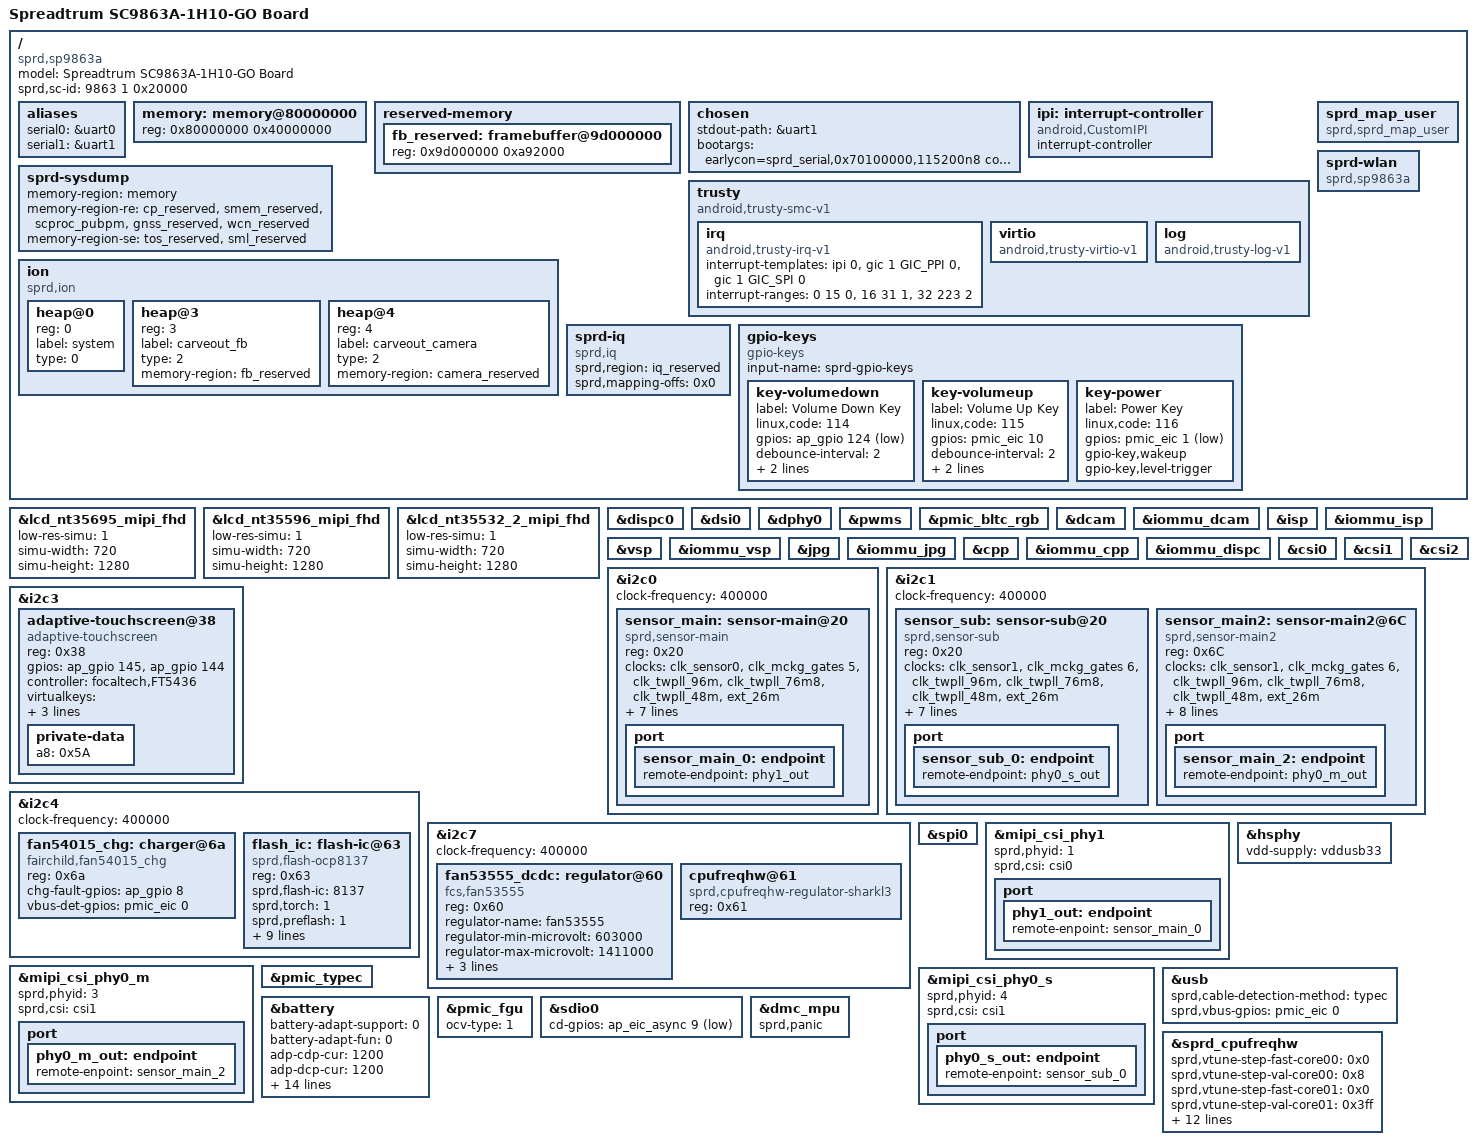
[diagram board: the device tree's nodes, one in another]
/*
 * Spreadtrum sharkl3 board DTS file
 *
 * Copyright (C) 2017, Spreadtrum Communications Inc.
 *
 * This file is licensed under a dual GPLv2 or X11 license.
 */
/dts-v1/;

#include "sc9863a.dtsi"
#include "sp9863a-go-common.dtsi"
#include "sc9863a-wcn.dtsi"

/ {
	model = "Spreadtrum SC9863A-1H10-GO Board";

	compatible = "sprd,sp9863a", "sprd,sc9863a";

	sprd,sc-id = <9863 1 0x20000>;

	aliases {
		serial0 = &uart0;
		serial1 = &uart1;
	};

	memory: memory@80000000 {
		device_type = "memory";
		reg = <0x80000000 0x40000000>;
	};

	reserved-memory {
		/* fb_size(HD): 3 * (head + payload) = 0xa91580, 4k align: 0xa92000 */
		fb_reserved: framebuffer@9d000000{
			reg = <0x9d000000 0xa92000>;
		};
	};

	chosen {
		stdout-path = &uart1;
		bootargs = "earlycon=sprd_serial,0x70100000,115200n8 console=ttyS1,115200n8 loglevel=1 init=/init root=/dev/mmcblk0p30 rootfstype=ext4 ro rootwait androidboot.hardware=s9863a1h10_go_32b androidboot.dtbo_idx=0 swiotlb=1 vmalloc=300M";
	};

	ipi: interrupt-controller {
		compatible = "android,CustomIPI";
		#interrupt-cells = <1>;
		interrupt-controller;
	};

	trusty {
		compatible = "android,trusty-smc-v1";

		irq {
			compatible = "android,trusty-irq-v1";
			interrupt-templates = <&ipi 0>,
						<&gic 1 GIC_PPI 0>,
						<&gic 1 GIC_SPI 0>;
			interrupt-ranges = < 0  15 0>,
						<16  31 1>,
						<32 223 2>;
		};

		virtio {
			compatible = "android,trusty-virtio-v1";
		};

		log {
			compatible = "android,trusty-log-v1";
		};
	};

	sprd-sysdump {
		memory-region = <&memory>;
		memory-region-re = <&cp_reserved>, <&smem_reserved>,
				   <&scproc_pubpm>, <&gnss_reserved>,
				   <&wcn_reserved>;
		memory-region-se = <&tos_reserved>, <&sml_reserved>;
	};

	sprd_map_user {
		compatible = "sprd,sprd_map_user";
	};

	ion {
		compatible = "sprd,ion";
		#address-cells = <1>;
		#size-cells = <0>;

		heap@0 {
			reg = <0>;
			label = "system";
			type = <0>;
		};

		heap@3 {
			reg = <3>;
			label = "carveout_fb";
			type = <2>;
			memory-region = <&fb_reserved>;
		};

		heap@4 {
			reg = <4>;
			label = "carveout_camera";
			type = <2>;
			memory-region = <&camera_reserved>;
		};
	};

	sprd-iq {
		compatible = "sprd,iq";
		sprd,region = <&iq_reserved>;
		sprd,mapping-offs = <0x0>;
	};

	sprd-wlan {
		compatible = "sprd,sp9863a";
	};

	gpio-keys {
		compatible = "gpio-keys";
		input-name = "sprd-gpio-keys";
		status = "okay";

		key-volumedown {
			label = "Volume Down Key";
			linux,code = <114>;
			gpios = <&ap_gpio 124 1>;
			debounce-interval = <2>;
			gpio-key,wakeup;
			gpio-key,level-trigger;
		};

		key-volumeup {
			label = "Volume Up Key";
			linux,code = <115>;
			gpios = <&pmic_eic 10 0>;
			debounce-interval = <2>;
			gpio-key,wakeup;
			gpio-key,level-trigger;
		};

		key-power {
			label = "Power Key";
			linux,code = <116>;
			gpios = <&pmic_eic 1 1>;
			gpio-key,wakeup;
			gpio-key,level-trigger;
		};
	};

};

&lcd_nt35695_mipi_fhd{
	low-res-simu = <1>;
	simu-width = <720>;
	simu-height = <1280>;
};

&lcd_nt35596_mipi_fhd{
	low-res-simu = <1>;
	simu-width = <720>;
	simu-height = <1280>;
};

&lcd_nt35532_2_mipi_fhd{
	low-res-simu = <1>;
	simu-width = <720>;
	simu-height = <1280>;
};

&dispc0 {
	status = "okay";
};

&dsi0 {
	status = "okay";
};

&dphy0 {
	status = "okay";
};

&pwms {
	status = "okay";
};

&pmic_bltc_rgb {
	status = "okay";
};

&dcam {
	status = "okay";
};

&iommu_dcam {
	status = "okay";
};

&isp {
	status = "okay";
};

&iommu_isp {
	status = "okay";
};

&vsp {
	status = "okay";
};

&iommu_vsp {
	status = "okay";
};

&jpg {
	status = "okay";
};

&iommu_jpg {
	status = "okay";
};

&cpp {
	status = "okay";
};

&iommu_cpp {
	status = "okay";
};

&iommu_dispc {
	status = "okay";
};

&csi0 {
	status = "okay";
};

&csi1 {
	status = "okay";
};

&csi2 {
	status = "okay";
};

&i2c0 {
	status = "okay";
	clock-frequency = <400000>;

	sensor_main: sensor-main@20 {
		compatible = "sprd,sensor-main";
		reg = <0x20>;
		clock-names = "clk_src","sensor_eb",
			"clk_96m","clk_76m8",
			"clk_48m","clk_26m";
		clocks = <&clk_sensor0>, <&clk_mckg_gates 5>,
			<&clk_twpll_96m>,<&clk_twpll_76m8>,
			<&clk_twpll_48m>,<&ext_26m>;
		vddio-supply = <&vddcamio>;
		vddcama-supply = <&vddcama>;
		vddcamd-supply = <&vddcamd>;
		vddcammot-supply = <&vddcammot>;
		reset-gpios = <&ap_gpio 44 0>;
		power-down-gpios = <&ap_gpio 46 0>;
		host = "dcam0";
		port {
			sensor_main_0: endpoint {
				remote-endpoint = <&phy1_out>;
			};
		};
	};
};

&i2c1 {
	status = "okay";
	clock-frequency = <400000>;

	sensor_sub: sensor-sub@20 {
		compatible = "sprd,sensor-sub";
		reg = <0x20>;
		clock-names = "clk_src","sensor_eb",
			"clk_96m","clk_76m8",
			"clk_48m","clk_26m";
		clocks = <&clk_sensor1>, <&clk_mckg_gates 6>,
			<&clk_twpll_96m>,<&clk_twpll_76m8>,
			<&clk_twpll_48m>,<&ext_26m>;
		vddio-supply = <&vddcamio>;
		vddcama-supply = <&vddcama>;
		vddcamd-supply = <&vddcamd>;
		vddcammot-supply = <&vddcammot>;
		reset-gpios = <&ap_gpio 41 0>;
		power-down-gpios = <&ap_gpio 40 0>;
		host = "dcam1";
		port {
			sensor_sub_0: endpoint {
				remote-endpoint = <&phy0_s_out>;
			};
		};
	};

	sensor_main2: sensor-main2@6C {
		compatible = "sprd,sensor-main2";
		reg = <0x6C>;
		clock-names = "clk_src","sensor_eb",
			"clk_96m","clk_76m8",
			"clk_48m","clk_26m";
		clocks = <&clk_sensor1>, <&clk_mckg_gates 6>,
			<&clk_twpll_96m>,<&clk_twpll_76m8>,
			<&clk_twpll_48m>,<&ext_26m>;
		vddio-supply = <&vddcamio>;
		vddcama-supply = <&vddcama>;
		vddcamd-supply = <&vddcamd>;
		vddcammot-supply = <&vddcammot>;
		dvdd-gpios=<&ap_gpio 62 0>;
		reset-gpios = <&ap_gpio 45 0>;
		power-down-gpios = <&ap_gpio 47 0>;
		host = "dcam1";
		port {
			sensor_main_2: endpoint {
				remote-endpoint = <&phy0_m_out>;
			};
		};
	};
};

&i2c3 {
	status = "okay";

	adaptive-touchscreen@38 {
		compatible = "adaptive-touchscreen";
		reg = <0x38>;
		gpios = <&ap_gpio 145 0
			&ap_gpio 144 0>;
		controller = "focaltech,FT5436";
		virtualkeys = <580 60 1320 60 45
			172 360 1320 60 45
			158 600 1320 60 45>;
		surface-width = <720>;
		surface-height = <1280>;
		private-data {
			a8 = /bits/ 8 <0x5A>;
		};
	};
};

&i2c4 {
	status = "okay";
	clock-frequency = <400000>;

	fan54015_chg: charger@6a {
		compatible = "fairchild,fan54015_chg";
		reg = <0x6a>;
		chg-fault-gpios = <&ap_gpio 8 0>;
		vbus-det-gpios = <&pmic_eic 0 0>;
	};

	flash_ic: flash-ic@63 {
		compatible = "sprd,flash-ocp8137";
		reg = <0x63>;
		sprd,flash-ic = <8137>;
		sprd,torch = <1>;
		sprd,preflash = <1>;
		sprd,highlight = <1>;
		sprd,torch-level = <128>;
		sprd,preflash-level = <128>;
		sprd,highlight-level = <128>;
		sprd,lvfm-enable = <1>;
		flash-torch-en-gpios = <&ap_gpio 88 0>;
		flash-chip-en-gpios = <&ap_gpio 89 0>;
		flash-en-gpios = <&ap_gpio 76 0>;
		flash-sync-gpios = <&ap_gpio 141 0>;
	};
};

&i2c7 {
	status = "okay";
	clock-frequency = <400000>;

	fan53555_dcdc: regulator@60 {
		compatible = "fcs,fan53555";
		reg = <0x60>;
		regulator-name = "fan53555";
		regulator-min-microvolt = <603000>;
		regulator-max-microvolt = <1411000>;
		regulator-ramp-delay = <64000>;
		regulator-always-on;
		fcs,suspend-voltage-selector = <1>;
	};

	/*virtual i2c device for cpu hw dvfs*/
	cpufreqhw@61 {
		compatible = "sprd,cpufreqhw-regulator-sharkl3";
		reg = <0x61>;
	};
};

&spi0 {
	/*used for fingerprint sensor*/
	status = "okay";
};

&mipi_csi_phy1 {
	status = "okay";
	sprd,phyid = <1>;
	sprd,csi = <&csi0>;
	status = "okay";
	port {
		phy1_out: endpoint {
			remote-enpoint = <&sensor_main_0>;
		};
	};
};

&mipi_csi_phy0_m {
	status = "okay";
	sprd,phyid = <3>;
	sprd,csi = <&csi1>;
	status = "okay";
	port {
		phy0_m_out: endpoint {
			remote-enpoint = <&sensor_main_2>;
		};
	};
};

&mipi_csi_phy0_s {
	status = "okay";
	sprd,phyid = <4>;
	sprd,csi = <&csi1>;
	status = "okay";
	port {
		phy0_s_out: endpoint {
			remote-enpoint = <&sensor_sub_0>;
		};
	};
};

&hsphy {
	vdd-supply = <&vddusb33>;
};

&usb {
	sprd,cable-detection-method = "typec";
	sprd,vbus-gpios = <&pmic_eic 0 0>;
};

&pmic_typec {
	status = "okay";
};

&battery {
	battery-adapt-support = <0>;
	battery-adapt-fun = <0>;
	adp-cdp-cur = <1200>;
	adp-dcp-cur = <1200>;
	adp-sdp-cur = <550>;
	adp-unknown-cur = <550>;
	chg-end-vol = <4350>;
	chg-end-vol-check = <4330>;
	chg-bat-safety-vol = <4430>;
	rechg-vol = <4270>;
	rsense-real = <200>;
	rint = <320>;
	cnom = <2780>;
	chg-polling-time = <10>;
	ocv-tab-vol = <4360 4249 4189 4133 4081 4034 3991
			3953 3910 3866 3836 3813 3795 3782
			3774 3765 3750 3726 3687 3658 3400>;
	ocv-tab-cap = <100  95   90   85   80   75   70
			65   60   55   50   45   40   35
			30   25   20   15   10   5    0>;
};

&pmic_fgu {
	ocv-type = <1>;
};

&sdio0 {
	 cd-gpios = <&ap_eic_async 9 1>;
};

&dmc_mpu {
	status = "okay";
	sprd,panic;
};

&sprd_cpufreqhw {
	sprd,vtune-step-fast-core00 = <0x0>;
	sprd,vtune-step-val-core00 = <0x8>;
	sprd,vtune-step-fast-core01 = <0x0>;
	sprd,vtune-step-val-core01 = <0x3ff>;
	sprd,vtune-vld-bit-core01 = <0x3f>;
	sprd,vtune-vld-bit-core00 = <0x3ff>;
	/*chnl0-[3:0],chnl0-[7:4],chnl2-[11:8]*/
	sprd,chnl-in-i2c = <0x000>;
	/*chnl_0-core1-i2c,chnl_1_2-core0-adi*/
	sprd,chnl-core-map = <0x01>;
	sprd,hold-val-core00 = <50>;
	sprd,pause-val-core00 = <5>;
	sprd,to-val-core00 = <800>;
	sprd,stable-val-core00 = <5>;
	sprd,hold-val-core01 = <25>;
	sprd,pause-val-core01 = <20>;
	sprd,to-val-core01 = <800>;
	sprd,stable-val-core01 = <25>;
};
